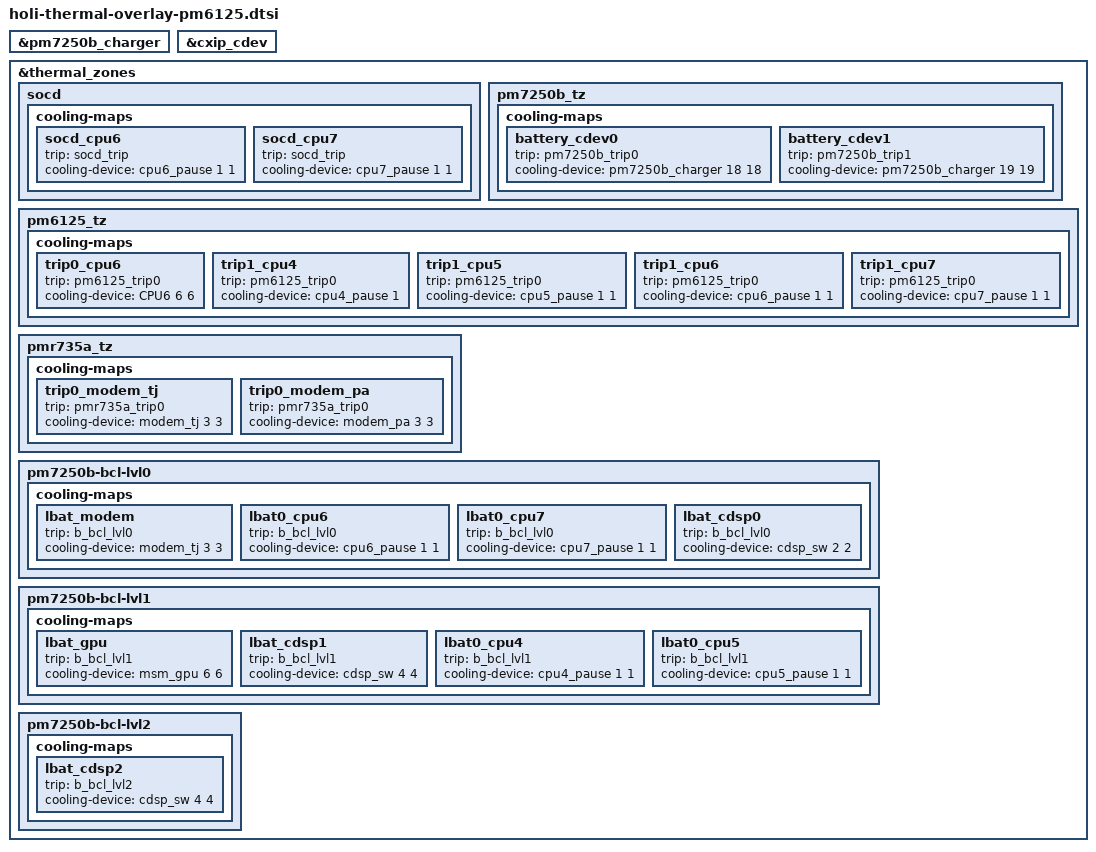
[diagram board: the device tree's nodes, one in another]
#include <dt-bindings/thermal/thermal_qti.h>

&pm7250b_charger {
	#cooling-cells = <2>;
};

&cxip_cdev {
	status = "ok";
};

&thermal_zones {
	socd {
		cooling-maps {
			socd_cpu6 {
				trip = <&socd_trip>;
				cooling-device = <&cpu6_pause 1 1>;
			};

			socd_cpu7 {
				trip = <&socd_trip>;
				cooling-device = <&cpu7_pause 1 1>;
			};
		};
	};

	pm7250b_tz {
		cooling-maps {
			battery_cdev0 {
				trip = <&pm7250b_trip0>;
				cooling-device = <&pm7250b_charger 18 18>;
			};

			battery_cdev1 {
				trip = <&pm7250b_trip1>;
				cooling-device = <&pm7250b_charger 19 19>;
			};
		};
	};

	pm6125_tz {
		cooling-maps {
			trip0_cpu6 {
				trip = <&pm6125_trip0>;
				cooling-device = <&CPU6 6 6>;
			};

			trip1_cpu4 {
				trip = <&pm6125_trip0>;
				cooling-device = <&cpu4_pause 1>;
			};

			trip1_cpu5 {
				trip = <&pm6125_trip0>;
				cooling-device = <&cpu5_pause 1 1>;
			};

			trip1_cpu6 {
				trip = <&pm6125_trip0>;
				cooling-device = <&cpu6_pause 1 1>;
			};

			trip1_cpu7 {
				trip = <&pm6125_trip0>;
				cooling-device = <&cpu7_pause 1 1>;
			};
		};
	};

	pmr735a_tz {
		cooling-maps {
			trip0_modem_tj {
				trip = <&pmr735a_trip0>;
				cooling-device = <&modem_tj 3 3>;
			};

			trip0_modem_pa {
				trip = <&pmr735a_trip0>;
				cooling-device = <&modem_pa 3 3>;
			};
		};
	};

	pm7250b-bcl-lvl0 {
		cooling-maps {
			lbat_modem {
				trip = <&b_bcl_lvl0>;
				cooling-device = <&modem_tj 3 3>;
			};

			lbat0_cpu6 {
				trip = <&b_bcl_lvl0>;
				cooling-device = <&cpu6_pause 1 1>;
			};

			lbat0_cpu7 {
				trip = <&b_bcl_lvl0>;
				cooling-device = <&cpu7_pause 1 1>;
			};

			lbat_cdsp0 {
				trip = <&b_bcl_lvl0>;
				cooling-device = <&cdsp_sw 2 2>;
			};
		};
	};

	pm7250b-bcl-lvl1 {
		cooling-maps {
			lbat_gpu {
				trip = <&b_bcl_lvl1>;
				cooling-device = <&msm_gpu 6 6>;
			};

			lbat_cdsp1 {
				trip = <&b_bcl_lvl1>;
				cooling-device = <&cdsp_sw 4 4>;
			};

			lbat0_cpu4 {
				trip = <&b_bcl_lvl1>;
				cooling-device = <&cpu4_pause 1 1>;
			};

			lbat0_cpu5 {
				trip = <&b_bcl_lvl1>;
				cooling-device = <&cpu5_pause 1 1>;
			};
		};
	};

	pm7250b-bcl-lvl2 {
		cooling-maps {
			lbat_cdsp2 {
				trip = <&b_bcl_lvl2>;
				cooling-device = <&cdsp_sw 4 4>;
			};
		};
	};
};
